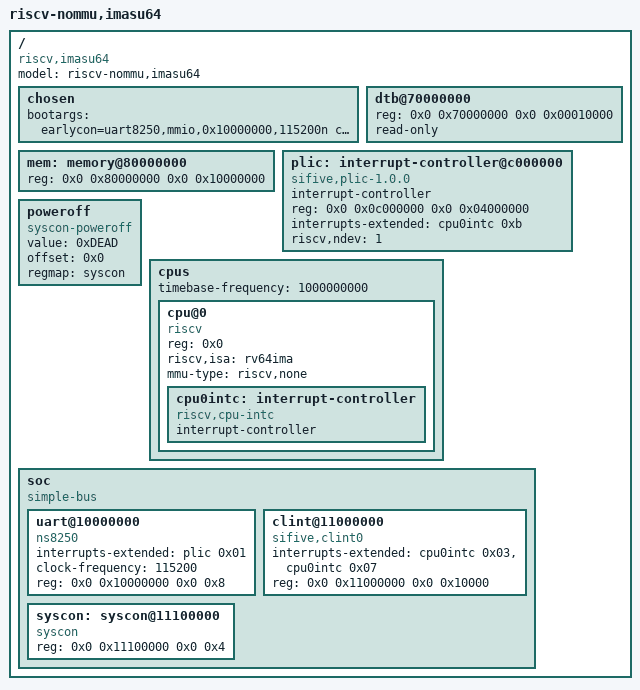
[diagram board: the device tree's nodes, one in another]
/dts-v1/;

/ {
	#address-cells = <0x02>;
	#size-cells = <0x02>;
	compatible = "riscv,imasu64";
	model = "riscv-nommu,imasu64";

	chosen {
		bootargs = "earlycon=uart8250,mmio,0x10000000,115200n console=ttyS0";
	};

	dtb@70000000 { // devicetree blob reserved memory at 0x70000000
		reg = <0x0 0x70000000 0x0 0x00010000>;
		read-only;
	};

	mem: memory@80000000 { // main memory starting at 0x80000000
		device_type = "memory";
		reg = <0x0 0x80000000 0x0 0x10000000>;
	};

	plic: interrupt-controller@c000000 { // plic at 0x0c000000
	    interrupt-controller;
	    #address-cells = <0x02>;
	    #interrupt-cells = <0x01>;
		reg = <0x0 0x0c000000 0x0 0x04000000>;
		interrupts-extended = <&cpu0intc 0xb>; // 0xb = M-mode external interrupt
		compatible = "sifive,plic-1.0.0";
		riscv,ndev = <1>; // number of external interrupts, not counting non-existing source 0
	};

	poweroff {
		compatible = "syscon-poweroff";
		value = <0xDEAD>;
		offset = <0x0>;
		regmap = <&syscon>;
	};

	cpus {
		#address-cells = <0x01>;
		#size-cells = <0x00>;

		timebase-frequency = <1000000000>; // nanoseconds per second

		cpu@0 {
			device_type = "cpu";
			reg = <0x0>; // cpu 0

			status = "okay";
			compatible = "riscv";
			riscv,isa = "rv64ima";
			mmu-type = "riscv,none";

			cpu0intc: interrupt-controller {
			    interrupt-controller;
				#interrupt-cells = <0x01>;
				compatible = "riscv,cpu-intc";
			};
		};
	};

	soc {
		#address-cells = <0x02>;
		#size-cells = <0x02>;
		compatible = "simple-bus";
		ranges;

		uart@10000000 { // ns8250 uart at 0x10000000
			interrupts-extended = <&plic 0x01>;
			clock-frequency = <115200>;
			reg = <0x0 0x10000000 0x0 0x8>;
			compatible = "ns8250";
		};

		clint@11000000 { // clint at 0x11000000
			// 0x3 = M-mode software interrupt, 0x7 = M-mode timer interrupt
			interrupts-extended = <&cpu0intc 0x03 &cpu0intc 0x07>;
			reg = <0x0 0x11000000 0x0 0x10000>;
			compatible = "sifive,clint0", "riscv,clint0";
		};

		syscon: syscon@11100000 {
		    reg = <0x0 0x11100000 0x0 0x4>;
			compatible = "syscon";
		};
	};
};
